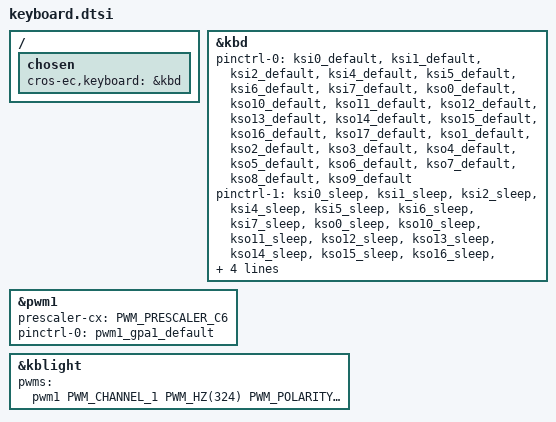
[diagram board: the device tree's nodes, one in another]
/* Copyright 2026 The ChromiumOS Authors
 * Use of this source code is governed by a BSD-style license that can be
 * found in the LICENSE file.
 */

#include "../rvp_keyboard.dtsi"

/ {
	chosen {
		cros-ec,keyboard = &kbd;
	};
};

&kbd {
	status = "okay";
	pinctrl-0 = <
		&ksi0_default
		&ksi1_default
		&ksi2_default
		&ksi4_default
		&ksi5_default
		&ksi6_default
		&ksi7_default
		&kso0_default
		&kso10_default
		&kso11_default
		&kso12_default
		&kso13_default
		&kso14_default
		&kso15_default
		&kso16_default
		&kso17_default
		&kso1_default
		&kso2_default
		&kso3_default
		&kso4_default
		&kso5_default
		&kso6_default
		&kso7_default
		&kso8_default
		&kso9_default
	>;
	pinctrl-1 = <
		&ksi0_sleep
		&ksi1_sleep
		&ksi2_sleep
		&ksi4_sleep
		&ksi5_sleep
		&ksi6_sleep
		&ksi7_sleep
		&kso0_sleep
		&kso10_sleep
		&kso11_sleep
		&kso12_sleep
		&kso13_sleep
		&kso14_sleep
		&kso15_sleep
		&kso16_sleep
		&kso17_sleep
		&kso1_sleep
		&kso2_sleep
		&kso3_sleep
		&kso4_sleep
		&kso5_sleep
		&kso6_sleep
		&kso7_sleep
		&kso8_sleep
		&kso9_sleep
	>;
	pinctrl-names = "default", "sleep";
};

&pwm1 {
	status = "okay";
	prescaler-cx = <PWM_PRESCALER_C6>;
	pinctrl-0 = <&pwm1_gpa1_default>;
	pinctrl-names = "default";
};

&kblight {
	pwms = <&pwm1 PWM_CHANNEL_1 PWM_HZ(324) PWM_POLARITY_NORMAL>;
};
